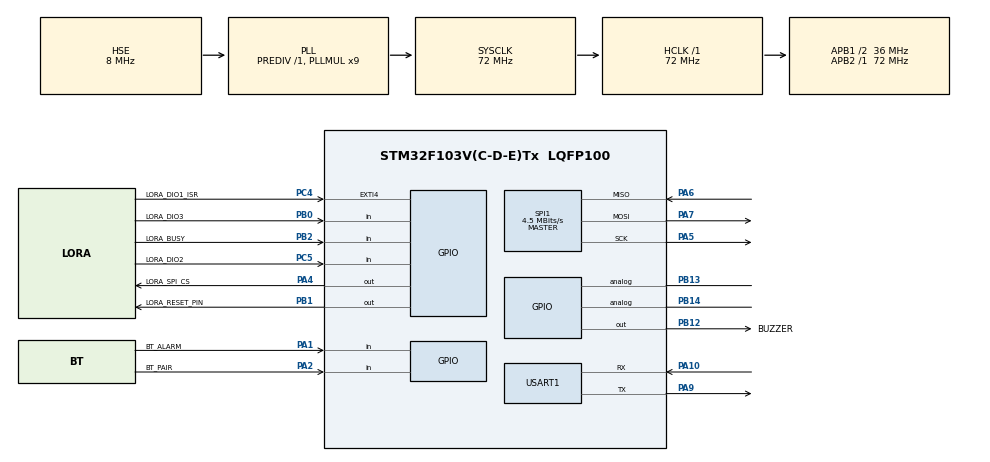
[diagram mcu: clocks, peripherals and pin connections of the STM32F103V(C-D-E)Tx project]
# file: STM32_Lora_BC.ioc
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IWDG.Prescaler=IWDG_PRESCALER_256
Mcu.Family=STM32F1
Mcu.Name=STM32F103V(C-D-E)Tx
Mcu.Package=LQFP100
NVIC.EXTI4_IRQn=true\:0\:0\:false\:false\:true\:true\:true\:true
NVIC.PriorityGroup=NVIC_PRIORITYGROUP_4
NVIC.USART1_IRQn=true\:0\:0\:false\:false\:true\:true\:true\:true
OSC_IN.Mode=HSE-External-Oscillator
OSC_IN.Signal=RCC_OSC_IN
OSC_OUT.Mode=HSE-External-Oscillator
OSC_OUT.Signal=RCC_OSC_OUT
PA1.GPIO_Label=BT_ALARM
PA1.GPIO_PuPd=GPIO_PULLUP
PA1.Signal=GPIO_Input
PA10.Mode=Asynchronous
PA10.Signal=USART1_RX
PA13.Mode=Serial_Wire
PA13.Signal=SYS_JTMS-SWDIO
PA14.Mode=Serial_Wire
PA14.Signal=SYS_JTCK-SWCLK
PA2.GPIO_Label=BT_PAIR
PA2.GPIO_PuPd=GPIO_PULLUP
PA2.Signal=GPIO_Input
PA4.GPIO_Label=LORA_SPI_CS
PA4.GPIO_PuPd=GPIO_PULLUP
PA4.GPIO_Speed=GPIO_SPEED_FREQ_HIGH
PA4.Signal=GPIO_Output
PA5.Mode=Full_Duplex_Master
PA5.Signal=SPI1_SCK
PA6.Mode=Full_Duplex_Master
PA6.Signal=SPI1_MISO
PA7.Mode=Full_Duplex_Master
PA7.Signal=SPI1_MOSI
PA9.Mode=Asynchronous
PA9.Signal=USART1_TX
PB0.GPIO_Label=LORA_DIO3
PB0.Signal=GPIO_Input
PB1.GPIO_Label=LORA_RESET_PIN
PB1.GPIO_Speed=GPIO_SPEED_FREQ_HIGH
PB1.Signal=GPIO_Output
PB12.GPIO_Label=BUZZER
PB12.GPIO_PuPd=GPIO_PULLUP
PB12.GPIO_Speed=GPIO_SPEED_FREQ_HIGH
PB12.Signal=GPIO_Output
PB13.Signal=GPIO_Analog
PB14.Signal=GPIO_Analog
PB2.GPIO_Label=LORA_BUSY
PB2.Signal=GPIO_Input
PC4.GPIO_Label=LORA_DIO1_ISR
PC4.Signal=GPXTI4
PC5.GPIO_Label=LORA_DIO2
PC5.Signal=GPIO_Input
ProjectManager.HeapSize=0x200
ProjectManager.StackSize=0x400
ProjectManager.TargetToolchain=MDK-ARM V5.32
RCC.AHBFreq_Value=72000000
RCC.APB1CLKDivider=RCC_HCLK_DIV2
RCC.APB1Freq_Value=36000000
RCC.APB1TimFreq_Value=72000000
RCC.APB2Freq_Value=72000000
RCC.APB2TimFreq_Value=72000000
RCC.HCLKFreq_Value=72000000
RCC.PLLMUL=RCC_PLL_MUL9
RCC.PLLSourceVirtual=RCC_PLLSOURCE_HSE
RCC.SYSCLKFreq_VALUE=72000000
RCC.SYSCLKSource=RCC_SYSCLKSOURCE_PLLCLK
RCC.USBFreq_Value=72000000
SPI1.BaudRatePrescaler=SPI_BAUDRATEPRESCALER_16
SPI1.CalculateBaudRate=4.5 MBits/s
SPI1.Direction=SPI_DIRECTION_2LINES
SPI1.Mode=SPI_MODE_MASTER
SPI1.VirtualType=VM_MASTER
USART1.VirtualMode=VM_ASYNC
VP_IWDG_VS_IWDG.Mode=IWDG_Activate
board=custom

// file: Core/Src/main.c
/* USER CODE BEGIN Header */
/**
  ******************************************************************************
  * @file           : main.c
  * @brief          : Main program body
  ******************************************************************************
  * @attention
  *
  * Copyright (c) 2023 STMicroelectronics.
  * All rights reserved.
  *
  * This software is licensed under terms that can be found in the LICENSE file
  * in the root directory of this software component.
  * If no LICENSE file comes with this software, it is provided AS-IS.
  *
  ******************************************************************************
  */
/* USER CODE END Header */
#include "main.h"
#include "iwdg.h"
#include "spi.h"
#include "usart.h"
#include "gpio.h"

void SystemClock_Config(void);

/* USER CODE BEGIN 0 */
 extern void app_main(void);

/* USER CODE END 0 */

int main(void)
{

  /* MCU Configuration--------------------------------------------------------*/

  /* Reset of all peripherals, Initializes the Flash interface and the Systick. */
  HAL_Init();

  /* Configure the system clock */
  SystemClock_Config();

  /* Initialize all configured peripherals */
  MX_GPIO_Init();
  MX_IWDG_Init();
  MX_SPI1_Init();
  MX_USART1_UART_Init();
  /* USER CODE BEGIN 2 */

  app_main();

  /* USER CODE END 2 */

  /* Infinite loop */
  while (1)
  {

  }
}

void SystemClock_Config(void)
{
  RCC_OscInitTypeDef RCC_OscInitStruct = {0};
  RCC_ClkInitTypeDef RCC_ClkInitStruct = {0};

  /** Initializes the RCC Oscillators according to the specified parameters
  * in the RCC_OscInitTypeDef structure.
  */
  RCC_OscInitStruct.OscillatorType = RCC_OSCILLATORTYPE_LSI|RCC_OSCILLATORTYPE_HSE;
  RCC_OscInitStruct.HSEState = RCC_HSE_ON;
  RCC_OscInitStruct.HSEPredivValue = RCC_HSE_PREDIV_DIV1;
  RCC_OscInitStruct.HSIState = RCC_HSI_ON;
  RCC_OscInitStruct.LSIState = RCC_LSI_ON;
  RCC_OscInitStruct.PLL.PLLState = RCC_PLL_ON;
  RCC_OscInitStruct.PLL.PLLSource = RCC_PLLSOURCE_HSE;
  RCC_OscInitStruct.PLL.PLLMUL = RCC_PLL_MUL9;
  if (HAL_RCC_OscConfig(&RCC_OscInitStruct) != HAL_OK)
  {
    Error_Handler();
  }

  /** Initializes the CPU, AHB and APB buses clocks
  */
  RCC_ClkInitStruct.ClockType = RCC_CLOCKTYPE_HCLK|RCC_CLOCKTYPE_SYSCLK
                              |RCC_CLOCKTYPE_PCLK1|RCC_CLOCKTYPE_PCLK2;
  RCC_ClkInitStruct.SYSCLKSource = RCC_SYSCLKSOURCE_PLLCLK;
  RCC_ClkInitStruct.AHBCLKDivider = RCC_SYSCLK_DIV1;
  RCC_ClkInitStruct.APB1CLKDivider = RCC_HCLK_DIV2;
  RCC_ClkInitStruct.APB2CLKDivider = RCC_HCLK_DIV1;

  if (HAL_RCC_ClockConfig(&RCC_ClkInitStruct, FLASH_LATENCY_2) != HAL_OK)
  {
    Error_Handler();
  }
}

/* USER CODE BEGIN 4 */
void HAL_GPIO_EXTI_Callback(uint16_t GPIO_Pin)
{
    extern void RadioOnDioIrq(void);
    RadioOnDioIrq();
}
/* USER CODE END 4 */

void Error_Handler(void)
{
  __disable_irq();
  while (1)
  {
  }
}
